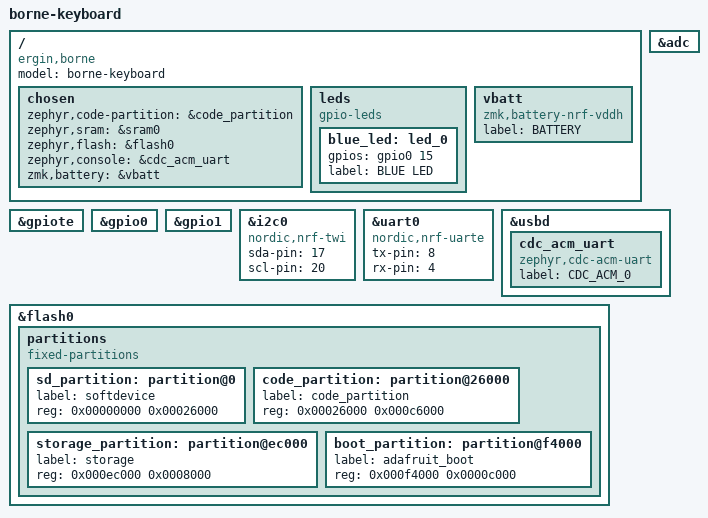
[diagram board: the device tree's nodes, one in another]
/*
 * Copyright (c) 2022 Gabriel Hansson
 *
 * SPDX-License-Identifier: MIT
 */

/dts-v1/;
#include <nordic/nrf52840_qiaa.dtsi>
#include <dt-bindings/led/led.h>


/ {
	model = "borne-keyboard";
	compatible = "ergin,borne";

	chosen {
		zephyr,code-partition = &code_partition;
		zephyr,sram = &sram0;
		zephyr,flash = &flash0;
		zephyr,console = &cdc_acm_uart;
		zmk,battery = &vbatt;
	};

	leds {
		compatible = "gpio-leds";
		blue_led: led_0 {
			gpios = <&gpio0 15 GPIO_ACTIVE_HIGH>;
			label = "BLUE LED";
		};
	};


	// TODO:
	// Vbat is currently designed to wrong the wrong pin. (no analog)
	// Update when V2 fixes this
	// vbatt: vbatt {
	// 	compatible = "zmk,battery-voltage-divider";
	// 	label = "BATTERY";
	// 	io-channels = <&adc 1>;
	// 	output-ohms = <10000000>;
	// 	full-ohms = <(10000000 + 4000000)>;
	// };
	// TEMP: placeholder for rev 2 using vddh voltage measurements
	vbatt: vbatt {
		compatible = "zmk,battery-nrf-vddh";
		label = "BATTERY";
	};
};

// Part of the vbat pin mishap, remove when fixed
&adc {
	status = "okay";
};

&gpiote {
	status = "okay";
};

&gpio0 {
	status = "okay";
};

&gpio1 {
	status = "okay";
};

//TODO: remove, but test that nothing breaks
&i2c0 {
	compatible = "nordic,nrf-twi";
	sda-pin = <17>;
	scl-pin = <20>;
};

&uart0 {
	compatible = "nordic,nrf-uarte";
	tx-pin = <8>;
	rx-pin = <4>;
};

&usbd {
	status = "okay";
	cdc_acm_uart: cdc_acm_uart {
		compatible = "zephyr,cdc-acm-uart";
		label = "CDC_ACM_0";
	};
};

&flash0 {
	/*
	 * Further reading:
	 * https://zmk.dev/blog/2020/10/03/bootloader-fix
	 * https://docs.zephyrproject.org/latest/build/dts/api/api.html#fixed-flash-partitions
	 * https://docs.zephyrproject.org/latest/build/dts/api/bindings/mtd/fixed-partitions.html?
	 */
	partitions {
		compatible = "fixed-partitions";
		#address-cells = <1>;
		#size-cells = <1>;

		sd_partition: partition@0 {
			label = "softdevice";
			// SoftDevice size/version e.g S140 v6 is 0x26000, v7 is 0x27000
			reg = <0x00000000 0x00026000>;
		};

		code_partition: partition@26000 {
			label = "code_partition";
			reg = <0x00026000 0x000c6000>;
		};

		storage_partition: partition@ec000 {
			label = "storage";
			reg = <0x000ec000 0x0008000>;
		};

		boot_partition: partition@f4000 {
			label = "adafruit_boot";
			reg = <0x000f4000 0x0000c000>;
		};
	};
};
